# M471 register map
File version: 1.0
Registers are 32-bit, read-write, reset 0x0 unless marked. A register's access mark holds for its fields unless they carry their own. Offsets are from the block's base; [hi:lo] are bit positions; {n}, {i} and the like mark numbered series; 'fields as' and 'values as' point back to an identical list.

## PDMA — PDMA Register Map
Base 0x40008000
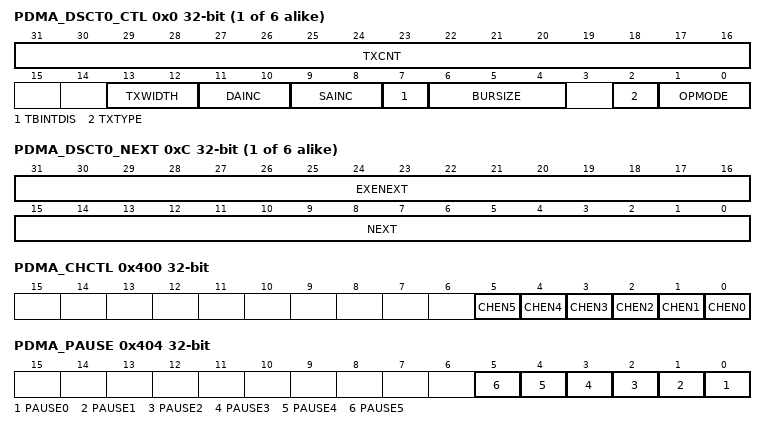
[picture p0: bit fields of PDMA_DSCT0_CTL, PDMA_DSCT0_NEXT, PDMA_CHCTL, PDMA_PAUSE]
{0x0+0x10*i} PDMA_DSCT{i}_CTL reset not defined (i=0..5) — Descriptor Table Control Register of PDMA Channel n
  [31:16] TXCNT — Transfer Count. The TXCNT represents the required number of PDMA transfer, the real transfer count is (TXCNT + 1); The maximum transfer count is 65536, every transfer may be byte, half-word or word that is dependent on TXWIDTH field. Note: When PDMA finishes each transfer data, this field will be decrease immediately.
  [13:12] TXWIDTH — Transfer Width Selection. This field is used for transfer width. Note: The PDMA transfer source address (PDMA_DSCT_SA) and PDMA transfer destination address (PDMA_DSCT_DA) should be alignment under the TXWIDTH selection
    0=One byte (8 bit) is transferred for every operation; 1=One half-word (16 bit) is transferred for every operation; 2=One word (32-bit) is transferred for every operation
  [11:10] DAINC — Destination Address Increment. This field is used to set the destination address increment size. Note: The fixed address function is not supported in memory to memory transfer type.
    3=No increment (fixed address)
  [9:8] SAINC — Source Address Increment. This field is used to set the source address increment size. Note: The fixed address function is not supported in memory to memory transfer type.
    3=No increment (fixed address)
  [7] TBINTDIS — Table Interrupt Disable Bit. This field can be used to decide whether to enable table interrupt or not. If the TBINTDIS bit is enabled it will not generates TDIFn(PDMA_TDSTS[15:0]) when PDMA controller finishes transfer task. Note: This function only for scatter-gather mode.
    0=Table interrupt Enabled; 1=Table interrupt Disabled
  [6:4] BURSIZE — Burst Size. Note: This field is only useful in burst transfer type.
    0=128 Transfers; 1=64 Transfers; 2=32 Transfers; 3=16 Transfers; 4=8 Transfers; 5=4 Transfers; 6=2 Transfers; 7=1 Transfers
  [2] TXTYPE — Transfer Type
    0=Burst transfer type; 1=Single transfer type
  [1:0] OPMODE — PDMA Operation Mode Selection. Note: Before filling new transfer task in the Descriptor Table, user must check the PDMA_INTSTS[1] to make sure the current task is complete.
    0=Idle state: Channel is stopped or this table is complete, when PDMA finish channel table task, OPMODE will be cleared to idle state automatically; 1=Basic mode: The descriptor table only has one task. When this task is finished, the PDMA_INTSTS[1] will be asserted; 2=Scatter-Gather mode: When operating in this mode, user must give the next descriptor table address in PDMA_DSCT_NEXT register; PDMA controller will ignore this task, then load the next task to execute
{0x4+0x10*i} PDMA_DSCT{i}_SA reset not defined (i=0..5) — Source Address Register of PDMA Channel n
  [31:0] SA — PDMA Transfer Source Address. This field indicates a 32-bit source address of PDMA controller.
{0x8+0x10*i} PDMA_DSCT{i}_DA reset not defined (i=0..5) — Destination Address Register of PDMA Channel n
  [31:0] DA — PDMA Transfer Destination Address. This field indicates a 32-bit destination address of PDMA controller.
{0xC+0x10*i} PDMA_DSCT{i}_NEXT reset not defined (i=0..5) — Next Scatter-gather Descriptor Table Offset Address of PDMA Channel n
  [31:16] EXENEXT — PDMA Execution Next Descriptor Table Offset. This field indicates the offset of next descriptor table address of current execution descriptor table in system memory. Note: write operation is useless in this field.
  [15:0] NEXT — PDMA Next Descriptor Table Offset. This field indicates the offset of the next descriptor table address in system memory. Write Operation: If the system memory based address is 0x2000_0000 (PDMA_SCATBA), and the next descriptor table is start from 0x2000_0100, then this field must fill in 0x0100. Read Operation: When operating in scatter-gather mode, the last two bits NEXT[1:0] will become reserved, and indicate the first next address of system memory. When operating in scatter-gather mode, the last two bits NEXT[1:0] will become scatter-gather mode control indicator as below. Note 1: The descriptor table address must be word boundary. Note 2: Before filled transfer task in the descriptor table, user must check if the descriptor table is complete.
    0=Idle mode; 1=operating in the basic mode (final scatter-gather table); 2=loading scatter-gather table from SRAM; 3=operating in the scatter-gather mode
{0x100+4i} PDMA_CURSCAT{i} ro reset not defined (i=0..5) — Current Scatter-gather Descriptor Table Address of PDMA Channel n
  [31:0] CURADDR — PDMA Current Description Address (Read Only). This field indicates a 32-bit current external description address of PDMA controller. Note: This field is read only and used for Scatter-Gather mode only to indicate the current external description address.
0x400 PDMA_CHCTL — PDMA Channel Control Register
  [all] fields
    0=PDMA channel [n] Disabled; 1=PDMA channel [n] Enabled
  [n] CHEN{n} (n=0..5) — PDMA Channel Enable Bits. Set this bit to 1 to enable PDMAn operation. Channel cannot be active if it is not set as enabled. Note: Setting the corresponding bit of PDMA_PAUSE or PDMA_CHRST register will also clear this bit.
0x404 PDMA_PAUSE wo — PDMA Transfer Pause Control Register
  [all] fields
    0=No effect; 1=Pause PDMA channel n transfer
  [n] PAUSE{n} (n=0..5) — PDMA Channel n Transfer Pause Control (Write Only)
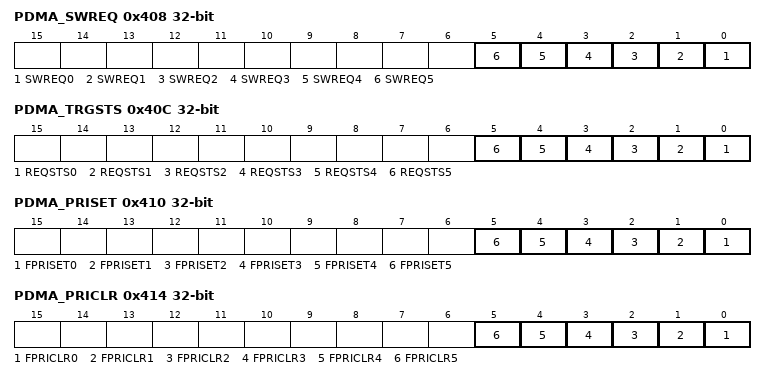
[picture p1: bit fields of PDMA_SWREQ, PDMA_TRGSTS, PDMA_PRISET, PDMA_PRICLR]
0x408 PDMA_SWREQ wo — PDMA Software Request Register
  [all] fields
    0=No effect; 1=Generate a software request
  [n] SWREQ{n} (n=0..5) — PDMA Software Request (Write Only). Set this bit to 1 to generate a software request to PDMA [n]. Note 1: User can read PDMA_TRGSTS register to know which channel is on active. Active flag may be triggered by software request or peripheral request. Note 2: If user does not enable corresponding PDMA channel, the software request will be ignored.
0x40C PDMA_TRGSTS ro — PDMA Channel Request Status Register
  [all] fields
    0=PDMA Channel n has no request; 1=PDMA Channel n has a request
  [n] REQSTS{n} (n=0..5) — PDMA Channel Request Status (Read Only). This flag indicates whether channel[n] have a request or not, no matter request from software or peripheral. When PDMA controller finishes channel transfer, this bit will be cleared automatically. Note: If user pauses or resets each PDMA transfer by setting PDMA_PAUSE or PDMA_CHRST register respectively, this bit will be cleared automatically after finishing the current transfer.
0x410 PDMA_PRISET — PDMA Fixed Priority Setting Register
  [all] fields
    0=No effect. Corresponding PDMA channel is round-robin priority; 1=Set PDMA channel [n] to fixed priority channel. Corresponding PDMA channel is fixed priority
  [n] FPRISET{n} (n=0..5) — PDMA Fixed Priority Setting. Set this bit to 1 to enable fixed priority level. Write Operation: Note: This field is only set to fixed priority; to clear fixed priority use PDMA_PRICLR register.
0x414 PDMA_PRICLR wo — PDMA Fixed Priority Clear Register
  [all] fields
    0=No effect; 1=Clear PDMA channel [n] fixed priority setting
  [n] FPRICLR{n} (n=0..5) — PDMA Fixed Priority Clear Bits (Write Only). Set this bit to 1 to clear fixed priority level. Note: User can read PDMA_PRISET register to know the channel priority.
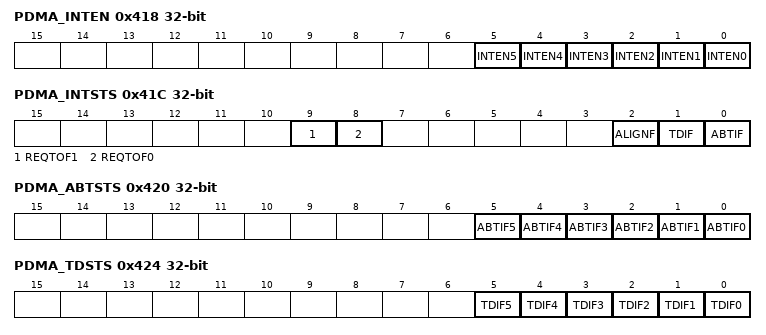
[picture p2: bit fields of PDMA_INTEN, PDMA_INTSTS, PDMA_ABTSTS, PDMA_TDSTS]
0x418 PDMA_INTEN — PDMA Interrupt Enable Register
  [all] fields
    0=PDMA channel n interrupt Disabled; 1=PDMA channel n interrupt Enabled.Note: The interrupt flag is time-out, abort, transfer done and align
  [n] INTEN{n} (n=0..5) — PDMA Interrupt Enable Bits. This field is used to enable PDMA channel[n] interrupt.
0x41C PDMA_INTSTS — PDMA Interrupt Status Register
  [9] REQTOF1 — Request Time-out Flag for Channel 1. This flag indicates that PDMA controller has waited peripheral request for a period defined by PDMA_TOC1, user can write 1 to clear these bits. Note: Please disable time-out function before clearing this bit.
    0=No request time-out; 1=Peripheral request time-out
  [8] REQTOF0 — Request Time-out Flag for Channel 0. This flag indicates that PDMA controller has waited peripheral request for a period defined by PDMA_TOC0, user can write 1 to clear these bits. Note: Please disable time-out function before clearing this bit.
    0=No request time-out; 1=Peripheral request time-out
  [2] ALIGNF ro — Transfer Alignment Interrupt Flag (Read Only)
    0=PDMA channel source address and destination address both follow transfer width setting; 1=PDMA channel source address or destination address is not follow transfer width setting
  [1] TDIF ro — Transfer Done Interrupt Flag (Read Only). This bit indicates that PDMA controller has finished transmission; User can read PDMA_TDSTS register to indicate which channel finished transfer.
    0=Not finished yet; 1=PDMA channel has finished transmission
  [0] ABTIF ro — PDMA Read/Write Target Abort Interrupt Flag (Read Only). This bit indicates that PDMA has target abort error; Software can read PDMA_ABTSTS register to find which channel has target abort error.
    0=No AHB bus ERROR response received; 1=AHB bus ERROR response received
0x420 PDMA_ABTSTS — PDMA Channel Read/Write Target Abort Flag Register
  [all] fields
    0=No AHB bus ERROR response received when channel n transfer; 1=AHB bus ERROR response received when channel n transfer
  [n] ABTIF{n} (n=0..5) — PDMA Read/Write Target Abort Interrupt Status Flag. This bit indicates which PDMA controller has target abort error; User can write 1 to clear these bits. Note: If channel n target abort, REQSRCn should set0 to disable peripheral request.
0x424 PDMA_TDSTS — PDMA Channel Transfer Done Flag Register
  [all] fields
    0=PDMA channel transfer has not finished; 1=PDMA channel has finished transmission
  [n] TDIF{n} (n=0..5) — Transfer Done Flag. This bit indicates whether PDMA controller channel transfer has been finished or not, user can write 1 to clear these bits.
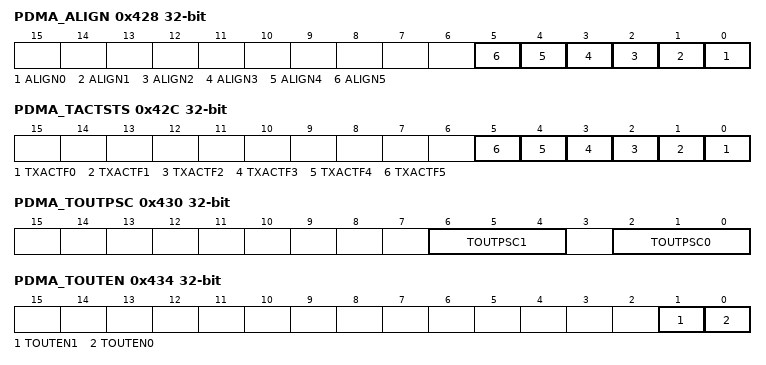
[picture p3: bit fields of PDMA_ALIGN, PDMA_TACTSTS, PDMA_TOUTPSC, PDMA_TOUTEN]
0x428 PDMA_ALIGN — PDMA Transfer Alignment Status Register
  [all] fields
    values as PDMA_INTSTS.ALIGNF
  [n] ALIGN{n} (n=0..5) — Transfer Alignment Flag. Note: Source address and destination address should be alignment.
0x42C PDMA_TACTSTS ro — PDMA Transfer Active Flag Register
  [all] fields
    0=PDMA channel is finished; 1=PDMA channel is active
  [n] TXACTF{n} (n=0..5) — Transfer on Active Flag (Read Only). This bit indicates which PDMA channel is in active.
0x430 PDMA_TOUTPSC — PDMA Time-out Prescaler Register
  [6:4] TOUTPSC1 — PDMA Channel 1 Time-out Clock Source Prescaler Bits
    0=PDMA channel 1 time-out clock source is HCLK/28; 1=PDMA channel 1 time-out clock source is HCLK/29; {v}=PDMA channel 1 time-out clock source is HCLK/{v+208} (v=2..7)
  [2:0] TOUTPSC0 — PDMA Channel 0 Time-out Clock Source Prescaler Bits
    0=PDMA channel 0 time-out clock source is HCLK/28; 1=PDMA channel 0 time-out clock source is HCLK/29; {v}=PDMA channel 0 time-out clock source is HCLK/{v+208} (v=2..7)
0x434 PDMA_TOUTEN — PDMA Time-out Enable Register
  [1] TOUTEN1 — PDMA Time-out Enable Bits
    0=PDMA Channel n time-out function Disabled; 1=PDMA Channel n time-out function Enabled
  [0] TOUTEN0 — PDMA Time-out Enable Bits
    values as TOUTEN1
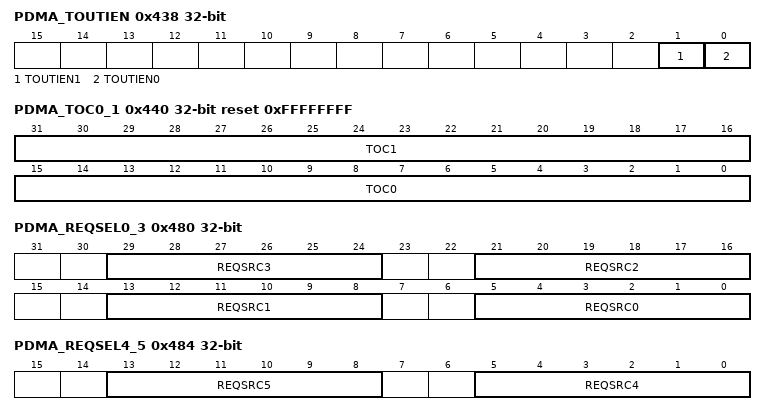
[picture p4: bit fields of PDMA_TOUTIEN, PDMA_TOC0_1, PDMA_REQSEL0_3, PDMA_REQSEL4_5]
0x438 PDMA_TOUTIEN — PDMA Time-out Interrupt Enable Register
  [1] TOUTIEN1 — PDMA Time-out Interrupt Enable Bits
    0=PDMA Channel n time-out interrupt Disabled; 1=PDMA Channel n time-out interrupt Enabled
  [0] TOUTIEN0 — PDMA Time-out Interrupt Enable Bits
    values as TOUTIEN1
0x43C PDMA_SCATBA reset 0x20000000 — PDMA Scatter-gather Descriptor Table Base Address Register
  [31:16] SCATBA — PDMA Scatter-gather Descriptor Table Address. In Scatter-Gather mode, this is the base address for calculating the next link - list address. The next link address equation is. Note: Only useful in Scatter-Gather mode.
0x440 PDMA_TOC0_1 reset 0xFFFFFFFF — PDMA Time-out Counter Ch1 and Ch0 Register
  [31:16] TOC1 — Time-out Counter for Channel 1. This controls the period of time-out function for channel 1. The calculation unit is based on TOUTPSC1 (PDMA_TOUTPSC[6:4]) clock.
  [15:0] TOC0 — Time-out Counter for Channel 0. This controls the period of time-out function for channel 0. The calculation unit is based on TOUTPSC0 (PDMA_TOUTPSC[2:0]) clock.
0x460 PDMA_CHRST — PDMA Channel Reset Register
  [5:0] CHnRST — Channel n Reset
    0=corresponding channel n is not reset; 1=corresponding channel n is reset
0x480 PDMA_REQSEL0_3 — PDMA Request Source Select Register 0
  [29:24] REQSRC3 — Channel 3 Request Source Selection. This filed defines which peripheral is connected to PDMA channel 3. User can configure the peripheral setting by REQSRC3. Note: The channel configuration is the same as REQSRC0 field. Please refer to the explanation of REQSRC0.
  [21:16] REQSRC2 — Channel 2 Request Source Selection. This filed defines which peripheral is connected to PDMA channel 2. User can configure the peripheral setting by REQSRC2. Note: The channel configuration is the same as REQSRC0 field. Please refer to the explanation of REQSRC0.
  [13:8] REQSRC1 — Channel 1 Request Source Selection. This filed defines which peripheral is connected to PDMA channel 1. User can configure the peripheral setting by REQSRC1. Note: The channel configuration is the same as REQSRC0 field. Please refer to the explanation of REQSRC0.
  [5:0] REQSRC0 — Channel 0 Request Source Selection. This filed defines which peripheral is connected to PDMA channel 0. User can configure the peripheral by setting REQSRC0. Note 1: A peripheral cannot be assigned to two channels at the same time. Note 2: This field is useless when transfer between memory and memory.
    0=Disable PDMA peripheral request; 1=Channel connects to UART0_TX; 2=Channel connects to UART0_RX; 3=Channel connects to UART1_TX; 4=Channel connects to UART1_RX; 5=Channel connects to UART2_TX; 6=Channel connects to UART2_RX; 7=Channel connects to UART3_TX; 8=Channel connects to UART3_RX; 9=Channel connects to UART4_TX; 10=Channel connects to UART4_RX; 11=Channel connects to UART5_TX; 12=Channel connects to UART5_RX; 13=Channel connects to SPI0_TX; 14=Channel connects to SPI0_RX; 15=Channel connects to SPI1_TX; 16=Channel connects to SPI1_RX; 17=Channel connects to EPWM0_P1_RX; 18=Channel connects to EPWM0_P2_RX; 19=Channel connects to EPWM0_P3_RX; 20=Channel connects to EPWM1_P1_RX; 21=Channel connects to EPWM1_P2_RX; 22=Channel connects to EPWM1_P3_RX; 23=Channel connects to I2C0_TX; 24=Channel connects to I2C0_RX; 25=Channel connects to I2C1_TX; 26=Channel connects to I2C1_RX; {v}=Channel connects to TMR{v-27} (v=27..30); 31=Channel connects to EADC0_RX; 32=Channel connects to DAC0_TX; {v}=Channel connects to EPWM0_CH{v-33}_TX (v=33..38); {v}=Channel connects to EPWM1_CH{v-39}_TX (v=39..44); 45=Channel connects to ACMP0; 46=Channel connects to ACMP1
0x484 PDMA_REQSEL4_5 — PDMA Request Source Select Register 1
  [13:8] REQSRC5 — Channel 5 Request Source Selection. This filed defines which peripheral is connected to PDMA channel 5. User can configure the peripheral setting by REQSRC5. Note: The channel configuration is the same as REQSRC0 field. Please refer to the explanation of REQSRC0.
  [5:0] REQSRC4 — Channel 4 Request Source Selection. This filed defines which peripheral is connected to PDMA channel 4. User can configure the peripheral setting by REQSRC4. Note: The channel configuration is the same as REQSRC0 field. Please refer to the explanation of REQSRC0.
